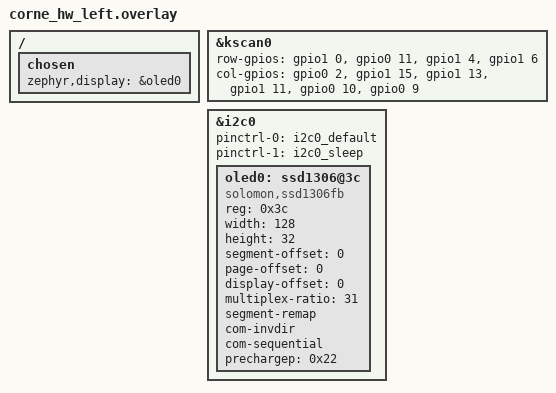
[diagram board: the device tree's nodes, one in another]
#include <dt-bindings/gpio/gpio.h>
#include "corne_hw.dtsi"

/ {
    chosen {
        zephyr,display = &oled0;
    };
};

&kscan0 {
    row-gpios = <&gpio1 0 GPIO_ACTIVE_HIGH>,
                <&gpio0 11 GPIO_ACTIVE_HIGH>,
                <&gpio1 4 GPIO_ACTIVE_HIGH>,
                <&gpio1 6 GPIO_ACTIVE_HIGH>;

    col-gpios = <&gpio0 2  (GPIO_ACTIVE_HIGH | GPIO_PULL_DOWN)>,
                <&gpio1 15 (GPIO_ACTIVE_HIGH | GPIO_PULL_DOWN)>,
                <&gpio1 13 (GPIO_ACTIVE_HIGH | GPIO_PULL_DOWN)>,
                <&gpio1 11 (GPIO_ACTIVE_HIGH | GPIO_PULL_DOWN)>,
                <&gpio0 10 (GPIO_ACTIVE_HIGH | GPIO_PULL_DOWN)>,
                <&gpio0 9  (GPIO_ACTIVE_HIGH | GPIO_PULL_DOWN)>;
};

&i2c0 {
    status = "okay";

    pinctrl-0 = <&i2c0_default>;
    pinctrl-1 = <&i2c0_sleep>;
    pinctrl-names = "default", "sleep";

    oled0: ssd1306@3c {
        compatible = "solomon,ssd1306fb";
        reg = <0x3c>;

        width = <128>;
        height = <32>;

        segment-offset = <0>;
        page-offset = <0>;
        display-offset = <0>;
        multiplex-ratio = <31>;

        segment-remap;
        com-invdir;
        com-sequential;

        prechargep = <0x22>;
    };
};
